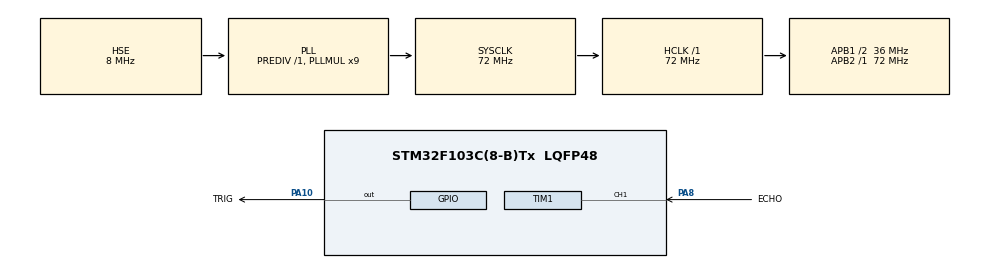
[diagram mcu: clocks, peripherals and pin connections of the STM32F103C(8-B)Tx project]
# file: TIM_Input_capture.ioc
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Mcu.Family=STM32F1
Mcu.Name=STM32F103C(8-B)Tx
Mcu.Package=LQFP48
NVIC.PriorityGroup=NVIC_PRIORITYGROUP_4
NVIC.TIM1_CC_IRQn=true\:0\:0\:false\:false\:true\:true\:true\:true
PA10.GPIO_Label=TRIG
PA10.Signal=GPIO_Output
PA13.Mode=Serial_Wire
PA13.Signal=SYS_JTMS-SWDIO
PA14.Mode=Serial_Wire
PA14.Signal=SYS_JTCK-SWCLK
PA8.GPIO_Label=ECHO
PA8.Signal=S_TIM1_CH1
PC14-OSC32_IN.Mode=LSE-External-Oscillator
PC14-OSC32_IN.Signal=RCC_OSC32_IN
PC15-OSC32_OUT.Mode=LSE-External-Oscillator
PC15-OSC32_OUT.Signal=RCC_OSC32_OUT
PD0-OSC_IN.Mode=HSE-External-Oscillator
PD0-OSC_IN.Signal=RCC_OSC_IN
PD1-OSC_OUT.Mode=HSE-External-Oscillator
PD1-OSC_OUT.Signal=RCC_OSC_OUT
ProjectManager.HeapSize=0x200
ProjectManager.StackSize=0x400
ProjectManager.TargetToolchain=CMake
RCC.AHBFreq_Value=72000000
RCC.APB1CLKDivider=RCC_HCLK_DIV2
RCC.APB1Freq_Value=36000000
RCC.APB1TimFreq_Value=72000000
RCC.APB2Freq_Value=72000000
RCC.APB2TimFreq_Value=72000000
RCC.HCLKFreq_Value=72000000
RCC.PLLMUL=RCC_PLL_MUL9
RCC.PLLSourceVirtual=RCC_PLLSOURCE_HSE
RCC.SYSCLKFreq_VALUE=72000000
RCC.SYSCLKSource=RCC_SYSCLKSOURCE_PLLCLK
RCC.USBFreq_Value=72000000
SH.S_TIM1_CH1.0=TIM1_CH1,Input_Capture1_from_TI1
TIM1.Channel-Input_Capture1_from_TI1=TIM_CHANNEL_1
TIM1.Channel-Input_Capture2_from_TI1_63=TIM_CHANNEL_2
TIM1.ICPolarity_CH2=TIM_INPUTCHANNELPOLARITY_FALLING
TIM1.Prescaler=72-1
VP_TIM1_VS_ClockSourceINT.Mode=Internal
VP_TIM1_VS_indirect_ch1.Mode=Input_Capture2_from_TI1_63
board=custom

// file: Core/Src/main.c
/* USER CODE BEGIN Header */
/**
  ******************************************************************************
  * @file           : main.c
  * @brief          : Main program body
  ******************************************************************************
  * @attention
  *
  * Copyright (c) 2026 STMicroelectronics.
  * All rights reserved.
  *
  * This software is licensed under terms that can be found in the LICENSE file
  * in the root directory of this software component.
  * If no LICENSE file comes with this software, it is provided AS-IS.
  *
  ******************************************************************************
  */
/* USER CODE END Header */
#include "main.h"
#include "tim.h"
#include "gpio.h"
#include "delay.h"

/* USER CODE BEGIN Includes */
#include "OLED.h"
/* USER CODE END Includes */

void SystemClock_Config(void);

int main(void) {

    /* MCU Configuration--------------------------------------------------------*/

    /* Reset of all peripherals, Initializes the Flash interface and the Systick. */
    HAL_Init();

    /* Configure the system clock */
    SystemClock_Config();

    /* Initialize all configured peripherals */
    MX_GPIO_Init();
    MX_TIM1_Init();
    /* USER CODE BEGIN 2 */
    OLED_Init();
    OLED_ShowString(1, 1, "DT:");
    OLED_ShowString(2, 1, "RE:");
    OLED_ShowString(3, 1, "FE:");
    HAL_TIM_IC_Start(&htim1, TIM_CHANNEL_1);    // 上升沿仅硬件捕获，不启用中断
    HAL_TIM_IC_Start_IT(&htim1, TIM_CHANNEL_2); // 下降沿捕获并产生中断

    /* USER CODE END 2 */

    /* Infinite loop */
    while (1) {

        // 清理捕获标志和计数器
        risingEdge = 0;
        fallingEdge = 0;
        // 每轮开始先标记为未完成，避免没有收到完整回波时沿用上次结果。
        captureComplete = 0;
        // 清除上一轮残留的捕获及溢出标志，防止旧捕获被误认为本轮数据。
        __HAL_TIM_CLEAR_FLAG(&htim1, TIM_FLAG_CC1 | TIM_FLAG_CC2 | TIM_FLAG_CC1OF | TIM_FLAG_CC2OF);
        __HAL_TIM_SET_COUNTER(&htim1, 0); // 重置计数器

        // 发送触发脉冲（持续10 us）并且等待回波返回或超时（40 ms）
        HAL_GPIO_WritePin(TRIG_GPIO_Port, TRIG_Pin, GPIO_PIN_SET);
        delay_us(10U);
        HAL_GPIO_WritePin(TRIG_GPIO_Port, TRIG_Pin, GPIO_PIN_RESET);

        // 等待下降沿中断完成捕获，最多等待 40 ms；HAL_Delay(1) 让出 CPU，捕获由硬件/中断完成。
        uint32_t captureStart = HAL_GetTick();
        while ((captureComplete == 0U) && ((HAL_GetTick() - captureStart) < 40U)) {
            HAL_Delay(1U);
        }
        /* USER CODE BEGIN 3 */

        // 只有捕获到完整回波才计算距离；超时或无回波时显示 0。
        OLED_ShowNum(1, 4, captureComplete ? return_distance_cm() : 0U, 6);
        OLED_ShowString(1, 11, "cm");
        OLED_ShowNum(2, 4, risingEdge, 6);
        OLED_ShowNum(3, 4, fallingEdge, 6);
        HAL_Delay(100);
    }
    /* USER CODE END 3 */
}

void SystemClock_Config(void) {
    RCC_OscInitTypeDef RCC_OscInitStruct = {0};
    RCC_ClkInitTypeDef RCC_ClkInitStruct = {0};

    /** Initializes the RCC Oscillators according to the specified parameters
  * in the RCC_OscInitTypeDef structure.
  */
    RCC_OscInitStruct.OscillatorType = RCC_OSCILLATORTYPE_HSE;
    RCC_OscInitStruct.HSEState = RCC_HSE_ON;
    RCC_OscInitStruct.HSEPredivValue = RCC_HSE_PREDIV_DIV1;
    RCC_OscInitStruct.HSIState = RCC_HSI_ON;
    RCC_OscInitStruct.PLL.PLLState = RCC_PLL_ON;
    RCC_OscInitStruct.PLL.PLLSource = RCC_PLLSOURCE_HSE;
    RCC_OscInitStruct.PLL.PLLMUL = RCC_PLL_MUL9;
    if (HAL_RCC_OscConfig(&RCC_OscInitStruct) != HAL_OK) {
        Error_Handler();
    }

    /** Initializes the CPU, AHB and APB buses clocks
  */
    RCC_ClkInitStruct.ClockType =
        RCC_CLOCKTYPE_HCLK | RCC_CLOCKTYPE_SYSCLK | RCC_CLOCKTYPE_PCLK1 | RCC_CLOCKTYPE_PCLK2;
    RCC_ClkInitStruct.SYSCLKSource = RCC_SYSCLKSOURCE_PLLCLK;
    RCC_ClkInitStruct.AHBCLKDivider = RCC_SYSCLK_DIV1;
    RCC_ClkInitStruct.APB1CLKDivider = RCC_HCLK_DIV2;
    RCC_ClkInitStruct.APB2CLKDivider = RCC_HCLK_DIV1;

    if (HAL_RCC_ClockConfig(&RCC_ClkInitStruct, FLASH_LATENCY_2) != HAL_OK) {
        Error_Handler();
    }
}

void Error_Handler(void) {
    __disable_irq();
    while (1) {
    }
}
